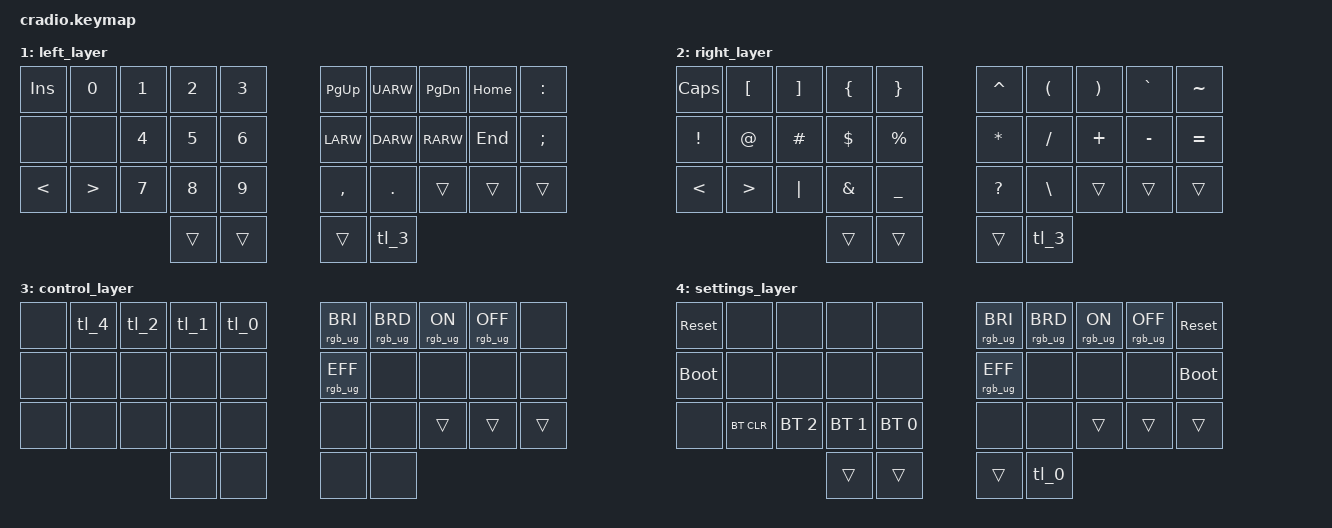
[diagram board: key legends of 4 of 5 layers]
// Copyright (c) 2022 The ZMK Contributors
// SPDX-License-Identifier: MIT

#include <behaviors.dtsi>
#include <dt-bindings/zmk/keys.h>
#include <dt-bindings/zmk/outputs.h>
#include <dt-bindings/zmk/bt.h>
#include <dt-bindings/led/led.h>
#include <dt-bindings/zmk/rgb.h>
#include "34keys.h"

&spi1 {
  compatible = "nordic,nrf-spim";
  status = "okay";
  mosi-pin = <33>;
  // Unused pins, needed for SPI definition, but not used by the ws2812 driver itself.
  sck-pin = <34>;
  miso-pin = <39>;

  led_strip: ws2812@0 {
    compatible = "worldsemi,ws2812-spi";
    label = "WS2812";

    /* SPI */
    reg = <0>; /* ignored, but necessary for SPI bindings */
    spi-max-frequency = <4000000>;

    /* WS2812 */
    chain-length = <10>; /* number of LEDs */
    spi-one-frame = <0x70>;
    spi-zero-frame = <0x40>;
    color-mapping = <LED_COLOR_ID_GREEN
                          LED_COLOR_ID_RED
                          LED_COLOR_ID_BLUE>;
  };
};

/ {
    chosen {
        zmk,underglow = &led_strip;
    };
};

// Home row mods macro
#define HRML(k1,k2,k3,k4) &ht LSHFT k1  &ht LGUI k2  &ht LCTRL k3  &ht LALT k4
#define HRMR(k1,k2,k3,k4) &ht RALT k1  &ht RCTRL k2  &ht RGUI k3  &ht RSHFT k4

/ {
    behaviors {
        ht: hold_tap {
            label = "hold_tap";
            compatible = "zmk,behavior-hold-tap";
            #binding-cells = <2>;
            flavor = "tap-preferred";
            tapping-term-ms = <220>;
            quick-tap-ms = <150>;
            global-quick-tap;
            bindings = <&kp>, <&kp>;
        };
    };
};  
#define COMBO(name, keypress, keypos) \
combo_##name {                        \
	timeout-ms = <100>;                \
	bindings = <keypress>;            \
	key-positions = <keypos>;         \
};

/ {
	combos {
		compatible = "zmk,combos";
		// invoke macros
		COMBO(tl_0,  &tl_0,   31  4)
		COMBO(tl_1,  &tl_1,   31  3)
		COMBO(tl_2,  &tl_2,   31  2)
		COMBO(tl_3,  &tl_3,   31  1)

	};
};

/ {	
    macros {
            ZMK_MACRO(tl_0,
    	    wait-ms = <0>;
    	    tap-ms = <0>;
            bindings
                = <&macro_press &to 0>
                , <&macro_tap &rgb_ug RGB_COLOR_HSB(128,100,100)>
                , <&macro_pause_for_release>
                , <&macro_release &to 0>
                , <&macro_tap &rgb_ug RGB_COLOR_HSB(210,100,100)>;
		)
		
	    ZMK_MACRO(tl_1,
	    wait-ms = <0>;
    	    tap-ms = <0>;
            bindings
                = <&macro_press &to 1>
                , <&macro_tap &rgb_ug RGB_COLOR_HSB(128,100,100)>
                , <&macro_pause_for_release>
                , <&macro_release &to 1>
                , <&macro_tap &rgb_ug RGB_COLOR_HSB(305,100,100)>;
		)
		
	    ZMK_MACRO(tl_2,
	    wait-ms = <0>;
    	    tap-ms = <0>;
            bindings
                = <&macro_press &to 2>
                , <&macro_tap &rgb_ug RGB_COLOR_HSB(128,100,100)>
                , <&macro_pause_for_release>
                , <&macro_release &to 2>
                , <&macro_tap &rgb_ug RGB_COLOR_HSB(55,90,55)>;
		)
		
	    ZMK_MACRO(tl_3,
	    wait-ms = <0>;
    	    tap-ms = <0>;
            bindings 
		= <&macro_press &to 3>
                , <&macro_tap &rgb_ug RGB_COLOR_HSB(128,100,100)>
                , <&macro_pause_for_release>
                , <&macro_release &to 3>
                , <&macro_tap &rgb_ug RGB_COLOR_HSB(0,0,100)>;
		)
	    ZMK_MACRO(tl_4,
	    wait-ms = <0>;
    	    tap-ms = <0>;
            bindings 
		= <&macro_press &to 4>
                , <&macro_tap &rgb_ug RGB_COLOR_HSB(128,100,100)>
                , <&macro_pause_for_release>
                , <&macro_release &to 4>
                , <&macro_tap &rgb_ug RGB_COLOR_HSB(0,100,100)>;
		)
    };
};

&caps_word {
    continue-list = <UNDERSCORE MINUS>;
};

/ {
    keymap {
        compatible = "zmk,keymap";
        default_layer {
            bindings = <
        //╭──────────┬──────────┬──────────┬──────────┬──────────╮   ╭──────────┬──────────┬──────────┬──────────┬──────────╮
        //│  Q       │  W       │  E       │  R       │  T       │   │  Y       │  U       │  I       │  O       │  P       │
            &kp Q      &kp W      &kp E      &kp R      &kp T          &kp Y      &kp U      &kp I      &kp O      &kp P
        //├──────────┼──────────┼──────────┼──────────┼──────────┤   ├──────────┼──────────┼──────────┼──────────┼──────────┤
        //│  A       │  S       │  D       │  F       │  G       │   │  H       │  J       │  K       │  L       │ ' "      │
            HRML(A,        S,         D,         F)     &kp G          &kp H      HRMR(J,        K,         L,        SQT)
        //├──────────┼──────────┼──────────┼──────────┼──────────┤   ├──────────┼──────────┼──────────┼──────────┼──────────┤
        //│  Z       │  X       │  C       │  V       │  B       │   │  N       │  M       │ ESC      │ DELETE   │ BACKSPACE│
            &kp Z      &kp X      &kp C      &kp V      &kp B          &kp N      &kp M      &kp ESC    &kp DEL    &kp BSPC
        //╰──────────┴──────────┴──────────┼──────────┼──────────┤   ├──────────┼──────────┼──────────┴──────────┴──────────╯
                                             &kp TAB    &kp ENTER      &kp SPACE  &tl_3
        //                                 ╰──────────┴──────────╯   ╰──────────┴──────────╯
            >;
        };

        left_layer {
            bindings = <
        //╭──────────┬──────────┬──────────┬──────────┬──────────╮   ╭──────────┬──────────┬──────────┬──────────┬──────────╮
        //│ INSERT   │  0       │  1       │  2       │  3       │   │ PAGE UP  │ UP       │ PAGE DN  │ HOME     │  :       │
            &kp INS    &kp N0     &kp N1     &kp N2     &kp N3         &kp PG_UP  &kp UARW  &kp PG_DN  &kp HOME   &kp COLON
        //├──────────┼──────────┼──────────┼──────────┼──────────┤   ├──────────┼──────────┼──────────┼──────────┼──────────┤
        //│          │          │  4       │  5       │  6       │   │ LEFT     │ DOWN     │ RIGHT    │ END      │  ;       │
            &none      &none      &kp N4     &kp N5     &kp N6         &kp LARW   &kp DARW   &kp RARW   &kp END    &kp SEMI
        //├──────────┼──────────┼──────────┼──────────┼──────────┤   ├──────────┼──────────┼──────────┼──────────┼──────────┤
        //│ <        │ >        │  7       │  8       │  9       │   │ ,        │ .        │          │          │          │
            &kp LT     &kp GT     &kp N7     &kp N8     &kp N9         &kp COMMA  &kp DOT    &trans     &trans     &trans 
        //╰──────────┴──────────┴──────────┼──────────┼──────────┤   ├──────────┼──────────┼──────────┴──────────┴──────────╯
                                             &trans     &trans         &trans     &tl_3
        //                                 ╰──────────┴──────────╯   ╰──────────┴──────────╯
            >;
        };

        right_layer {
            bindings = <
        //╭──────────┬──────────┬──────────┬──────────┬──────────╮   ╭──────────┬──────────┬──────────┬──────────┬──────────╮
        //│ CAPSLOCK │  [       │  ]       │  {       │ }        │   │  ^       │  (       │  )       │  `       │  ~       │
            &kp CAPS   &kp LBKT   &kp RBKT   &kp LBRC   &kp RBRC       &kp CARET  &kp LPAR   &kp RPAR   &kp GRAVE  &kp TILDE
        //├──────────┼──────────┼──────────┼──────────┼──────────┤   ├──────────┼──────────┼──────────┼──────────┼──────────┤
        //│  !       │  @       │  #       │  $       │  %       │   │  *       │  /       │  +       │  -       │  =       │
            &kp EXCL   &kp AT     &kp HASH   &kp DLLR   &kp PRCNT      &kp ASTRK  &kp FSLH   &kp PLUS   &kp MINUS  &kp EQUAL
        //├──────────┼──────────┼──────────┼──────────┼──────────┤   ├──────────┼──────────┼──────────┼──────────┼──────────┤
        //│  <       │  >       │  |       │  &       │  _       │   │  ?       │  \       │          │          │          │
            &kp LT     &kp GT     &kp PIPE   &kp AMPS   &kp UNDER      &kp QMARK  &kp BSLH   &trans     &trans     &trans
        //╰──────────┴──────────┴──────────┼──────────┼──────────┤   ├──────────┼──────────┼──────────┴──────────┴──────────╯
                                             &trans     &trans         &trans     &tl_3
        //                                 ╰──────────┴──────────╯   ╰──────────┴──────────╯
            >;
        };

        control_layer {
            bindings = <
        //╭──────────┬──────────┬──────────┬──────────┬──────────╮   ╭──────────┬──────────┬──────────┬──────────┬──────────╮
        //│          │          │          │          │          │   │   LED +  │  LED -   │  LED ON  │ LED OFF  │          │
            &none      &tl_4      &tl_2      &tl_1      &tl_0       &rgb_ug RGB_BRI &rgb_ug RGB_BRD &rgb_ug RGB_ON &rgb_ug RGB_OFF &none
        //├──────────┼──────────┼──────────┼──────────┼──────────┤   ├──────────┼──────────┼──────────┼──────────┼──────────┤
        //│          │          │          │          │          │   │ LED EFF  │          │          │          │          │
            &none      &none      &none      &none      &none       &rgb_ug RGB_EFF &none    &none      &none      &none
        //├──────────┼──────────┼──────────┼──────────┼──────────┤   ├──────────┼──────────┼──────────┼──────────┼──────────┤
        //│          │          │          │          │          |   |          │          │          │          │          │
            &none      &none      &none      &none      &none          &none      &none      &trans     &trans     &trans   
        //╰──────────┴──────────┴──────────┼──────────┼──────────┤   ├──────────┼──────────┼──────────┴──────────┴──────────╯
                                             &none      &none          &none     &none
        //                                 ╰──────────┴──────────╯   ╰──────────┴──────────╯
            >;
        };
	
	settings_layer {
            bindings = <
        //╭──────────┬──────────┬──────────┬──────────┬──────────╮   ╭──────────┬──────────┬──────────┬──────────┬──────────╮
        //│ RESET    │          │          │          │          │   │   LED +  │  LED -   │  LED ON  │ LED OFF  │  RESET   │
            &sys_reset     &none      &none      &none      &none       &rgb_ug RGB_BRI &rgb_ug RGB_BRD &rgb_ug RGB_ON &rgb_ug RGB_OFF &sys_reset
        //├──────────┼──────────┼──────────┼──────────┼──────────┤   ├──────────┼──────────┼──────────┼──────────┼──────────┤
        //│BOOTLOADER│          │          │          │          │   │ LED EFF  │          │          │          │BOOTLOADER│
          &bootloader  &none      &none      &none      &none       &rgb_ug RGB_EFF &none    &none      &none      &bootloader
        //├──────────┼──────────┼──────────┼──────────┼──────────┤   ├──────────┼──────────┼──────────┼──────────┼──────────┤
        //│          │ CLEAR BT │ PROFILE 2│ PROFILE 1│ PROFILE 0|   |          │          │          │          │          │
            &none    &bt BT_CLR &bt BT_SEL 2 &bt BT_SEL 1 &bt BT_SEL 0 &none        &none    &trans     &trans     &trans   
        //╰──────────┴──────────┴──────────┼──────────┼──────────┤   ├──────────┼──────────┼──────────┴──────────┴──────────╯
                                             &trans     &trans         &trans     &tl_0
        //                                 ╰──────────┴──────────╯   ╰──────────┴──────────╯
            >;
        };
    };
};
